# CY8C5868AXI_LP035 register map
File version: 0.1
CY8C58LP
Registers are 8-bit, read-write, no defined reset value unless marked. A register's access mark holds for its fields unless they carry their own. Offsets are from the block's base; lines under a group give offsets from that group; [hi:lo] are bit positions; {n}, {i} and the like mark numbered series; 'fields as' and 'values as' point back to an identical list; <NAME> marks a mode.

## Memory map
0x00000000 FanController
0x00000000 Select6820
0x00000000 Timer_1
0x00000000 UART_1 — UART
0x00000000 current_timer
0x00000000 CAN_1
0x00000000 SOC_Timer
0x00000000 PWM
0x00000000 ADC_current

## FanController
Base 0x00000000
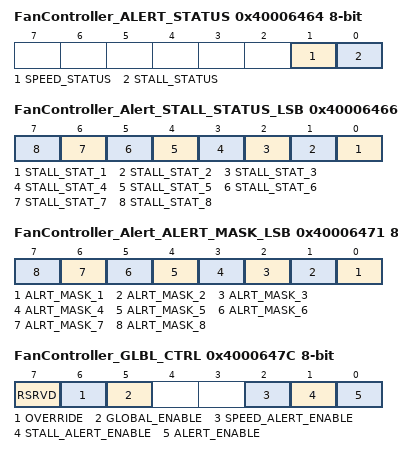
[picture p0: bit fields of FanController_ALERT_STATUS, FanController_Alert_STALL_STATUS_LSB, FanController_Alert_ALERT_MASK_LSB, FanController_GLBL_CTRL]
0x40006464 FanController_ALERT_STATUS — Alert Status Register
  [1] SPEED_STATUS ro — Speed status for all Fans
    0=NO_SPEED_ERROR (No speed error occurred); 1=SPEED_ERROR (Speed error is occurred)
  [0] STALL_STATUS ro — Stall status for all Fans
    0=NO_STALL (No stall occurred); 1=STALL (Stall is occurred)
0x40006466 FanController_Alert_STALL_STATUS_LSB — Stall Status LSB Register
  [n-1] STALL_STAT_{n} (n=1..8) — Stall status for Fan{n}
0x40006471 FanController_Alert_ALERT_MASK_LSB — Alert Mask LSB Register
  [n-1] ALRT_MASK_{n} (n=1..8) — Alert Mask for Fan{n}
0x4000647C FanController_GLBL_CTRL — Global Control Register
  [7] RSRVD ro — Reserved
  [6] OVERRIDE — HW mode override bit
    0=OVRD_DISABLED (HW control not overrided); 1=OVRD_ENABLED (HW control overrided)
  [5] GLOBAL_ENABLE — Global enable signal for the component
    0=COMP_DISABLED (Component disabled); 1=COMP_ENABLED (Component is enabled)
  [2] SPEED_ALERT_ENABLE — Speed alert enable signal
    0=SPEED_ALRT_DIS (Generation of speed alert is disabled); 1=SPEED_ALRT_EN (Generation of speed alert is enabled)
  [1] STALL_ALERT_ENABLE — Stall alert enable signal
    0=STALL_ALRT_DIS (Generation of stall alert is disabled); 1=STALL_ALRT_EN (Generation of stall alert is enabled)
  [0] ALERT_ENABLE — Global alert enable signal
    0=ALERTS_DIS (Generation of all alerts is disabled); 1=ALERTS_EN (Generation of alerts is enabled)

## Select6820
Base 0x00000000
0x40006476 Select6820_CONTROL_REG

## Timer_1
Base 0x00000000
0x4000640A Timer_1_COUNTER 32-bit — UDB.A0 - Current Down Counter Value
0x4000642A Timer_1_PERIOD 32-bit — UDB.D0 - Assigned Period
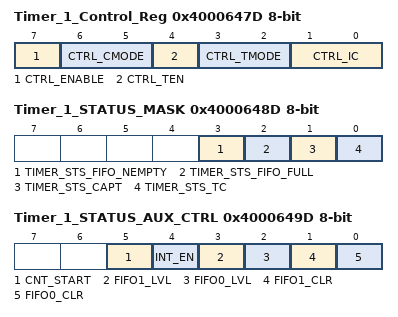
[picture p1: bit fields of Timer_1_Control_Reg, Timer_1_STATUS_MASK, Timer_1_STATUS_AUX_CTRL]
0x4000647D Timer_1_Control_Reg — UDB Control Register - Assigned Control Register Value
  [7] CTRL_ENABLE — Enable the Timer
  [6:5] CTRL_CMODE — Capture Mode
  [4] CTRL_TEN — Trigger Enable Bit
  [3:2] CTRL_TMODE — Trigger Mode
  [1:0] CTRL_IC — Interrupt Count
0x4000648D Timer_1_STATUS_MASK — UDB Status bits Interrupt Mask Enable Register
  [3] TIMER_STS_FIFO_NEMPTY ro — FIFO Empty status
  [2] TIMER_STS_FIFO_FULL ro — FIFO Full Status
  [1] TIMER_STS_CAPT ro — Enables the Interrupt on Capture
  [0] TIMER_STS_TC ro — Enables the Interrupt on TC
0x4000649D Timer_1_STATUS_AUX_CTRL — UDB Auxilliary Control Register
  [5] CNT_START — FIFO0 clear
    0=E_CNT_START0 (Disable counter); 1=E_CNT_START1 (Enable counter)
  [4] INT_EN
    0=E_INT_EN0 (Interrupt disabled); 1=E_INT_EN1 (Interrupt enabled)
  [3] FIFO1_LVL — FIFO level
    0=E_FIFO_LVL_0 (FIFO LVL: input mode: FIFO not full; output mode: FIFO not empty); 1=E_FIFO_LVL_1 (FIFO LVL: input mode: FIFO at least 1/2 empty; output mode: FIFO at least 1/2 full)
  [2] FIFO0_LVL — FIFO level
    values as FIFO1_LVL
  [1] FIFO1_CLR — FIFO1 clear
    0=E_FIFO_CLR_0 (Normal FIFO operation); 1=E_FIFO_CLR_1 (Clear FIFO state)
  [0] FIFO0_CLR — FIFO0 clear
    values as FIFO1_CLR

## UART_1 — UART
Base 0x00000000
0x40006420 RX_UART_1_RX_ADDRESS1 — RX Address1 Register
0x40006430 RX_UART_1_RX_ADDRESS2 — RX Address2 Register
0x40006440 RX_UART_1_RX_DATA — RX Data Register
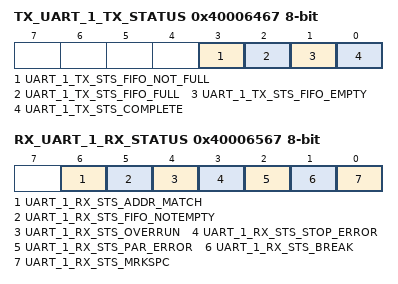
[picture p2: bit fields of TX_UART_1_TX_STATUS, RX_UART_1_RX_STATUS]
0x40006467 TX_UART_1_TX_STATUS — TX status register
  [3] UART_1_TX_STS_FIFO_NOT_FULL ro, [2] UART_1_TX_STS_FIFO_FULL ro, [1] UART_1_TX_STS_FIFO_EMPTY ro, [0] UART_1_TX_STS_COMPLETE ro
0x40006544 TX_UART_1_TX_DATA — TX Data Register
0x40006567 RX_UART_1_RX_STATUS — RX status register
  [6] UART_1_RX_STS_ADDR_MATCH ro, [5] UART_1_RX_STS_FIFO_NOTEMPTY ro, [4] UART_1_RX_STS_OVERRUN ro, [3] UART_1_RX_STS_STOP_ERROR ro, [2] UART_1_RX_STS_PAR_ERROR ro, [1] UART_1_RX_STS_BREAK ro, [0] UART_1_RX_STS_MRKSPC ro
